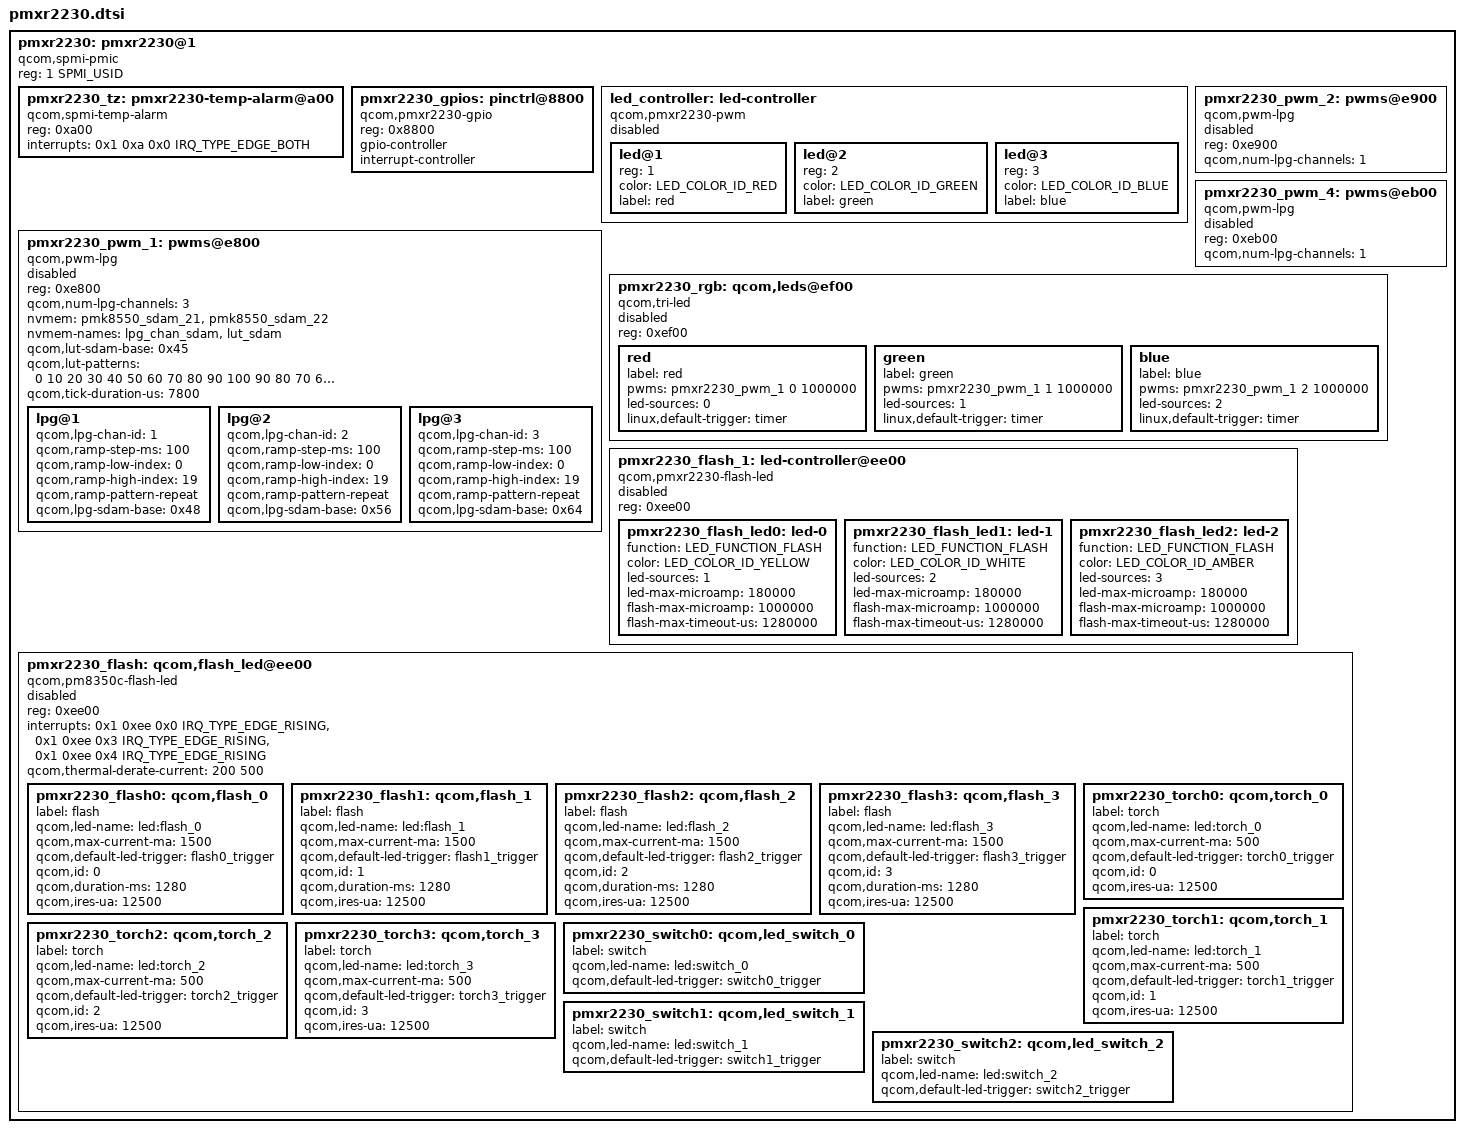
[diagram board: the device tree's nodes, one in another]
// SPDX-License-Identifier: BSD-3-Clause
/*
 * Copyright (c) Qualcomm Technologies, Inc. and/or its subsidiaries.
 */

#include <dt-bindings/interrupt-controller/irq.h>
#include <dt-bindings/spmi/spmi.h>
#include <dt-bindings/leds/common.h>

pmxr2230: pmxr2230@1 {
	compatible = "qcom,spmi-pmic";
	reg = <1 SPMI_USID>;
	#address-cells = <1>;
	#size-cells = <0>;

	pmxr2230_tz: pmxr2230-temp-alarm@a00 {
		compatible = "qcom,spmi-temp-alarm";
		reg = <0xa00>;
		interrupts = <0x1 0xa 0x0 IRQ_TYPE_EDGE_BOTH>;
		#thermal-sensor-cells = <0>;
	};

	pmxr2230_gpios: pinctrl@8800 {
		compatible = "qcom,pmxr2230-gpio";
		reg = <0x8800>;
		gpio-controller;
		#gpio-cells = <2>;
		interrupt-controller;
		#interrupt-cells = <2>;
	};

	led_controller: led-controller {
		compatible = "qcom,pmxr2230-pwm", "qcom,pm8350c-pwm";
		#address-cells = <1>;
		#size-cells = <0>;
		status = "disabled";

		led@1 {
			reg = <1>;
			color = <LED_COLOR_ID_RED>;
			label = "red";
		};

		led@2 {
			reg = <2>;
			color = <LED_COLOR_ID_GREEN>;
			label = "green";
		};

		led@3 {
			reg = <3>;
			color = <LED_COLOR_ID_BLUE>;
			label = "blue";
		};
	};

	pmxr2230_pwm_1: pwms@e800 {
		compatible = "qcom,pwm-lpg";
		reg = <0xe800>;
		reg-names = "lpg-base";
		#pwm-cells = <2>;
		qcom,num-lpg-channels = <3>;
		nvmem = <&pmk8550_sdam_21 &pmk8550_sdam_22>;
		nvmem-names = "lpg_chan_sdam", "lut_sdam";
		qcom,lut-sdam-base = <0x45>;
		qcom,lut-patterns = <0 10 20 30 40 50 60 70 80 90 100
				     90 80 70 60 50 40 30 20 10 0>;
		qcom,tick-duration-us = <7800>;
		status = "disabled";

		lpg@1 {
			qcom,lpg-chan-id = <1>;
			qcom,ramp-step-ms = <100>;
			qcom,ramp-low-index = <0>;
			qcom,ramp-high-index = <19>;
			qcom,ramp-pattern-repeat;
			qcom,lpg-sdam-base = <0x48>;
		};

		lpg@2 {
			qcom,lpg-chan-id = <2>;
			qcom,ramp-step-ms = <100>;
			qcom,ramp-low-index = <0>;
			qcom,ramp-high-index = <19>;
			qcom,ramp-pattern-repeat;
			qcom,lpg-sdam-base = <0x56>;
		};

		lpg@3 {
			qcom,lpg-chan-id = <3>;
			qcom,ramp-step-ms = <100>;
			qcom,ramp-low-index = <0>;
			qcom,ramp-high-index = <19>;
			qcom,ramp-pattern-repeat;
			qcom,lpg-sdam-base = <0x64>;
		};
	};

	pmxr2230_pwm_2: pwms@e900 {
		compatible = "qcom,pwm-lpg";
		reg = <0xe900>;
		reg-names = "lpg-base";
		#pwm-cells = <2>;
		qcom,num-lpg-channels = <1>;
		status = "disabled";
	};

	pmxr2230_pwm_4: pwms@eb00 {
		compatible = "qcom,pwm-lpg";
		reg = <0xeb00>;
		reg-names = "lpg-base";
		#pwm-cells = <2>;
		qcom,num-lpg-channels = <1>;
		status = "disabled";
	};

	pmxr2230_rgb: qcom,leds@ef00 {
		compatible = "qcom,tri-led";
		reg = <0xef00>;
		status = "disabled";

		red {
			label = "red";
			pwms = <&pmxr2230_pwm_1 0 1000000>;
			led-sources = <0>;
			linux,default-trigger = "timer";
		};

		green {
			label = "green";
			pwms = <&pmxr2230_pwm_1 1 1000000>;
			led-sources = <1>;
			linux,default-trigger = "timer";
		};

		blue {
			label = "blue";
			pwms = <&pmxr2230_pwm_1 2 1000000>;
			led-sources = <2>;
			linux,default-trigger = "timer";
		};
	};

	pmxr2230_flash_1: led-controller@ee00 {
		compatible = "qcom,pmxr2230-flash-led", "qcom,spmi-flash-led";
		reg = <0xee00>;
		status = "disabled";

		pmxr2230_flash_led0: led-0 {
			function = LED_FUNCTION_FLASH;
			color = <LED_COLOR_ID_YELLOW>;
			led-sources = <1>;
			led-max-microamp = <180000>;
			flash-max-microamp = <1000000>;
			flash-max-timeout-us = <1280000>;
		};

		pmxr2230_flash_led1: led-1 {
			function = LED_FUNCTION_FLASH;
			color = <LED_COLOR_ID_WHITE>;
			led-sources = <2>;
			led-max-microamp = <180000>;
			flash-max-microamp = <1000000>;
			flash-max-timeout-us = <1280000>;
		};

		pmxr2230_flash_led2: led-2 {
			function = LED_FUNCTION_FLASH;
			color = <LED_COLOR_ID_AMBER>;
			led-sources = <3>;
			led-max-microamp = <180000>;
			flash-max-microamp = <1000000>;
			flash-max-timeout-us = <1280000>;
		};
	};

	pmxr2230_flash: qcom,flash_led@ee00 {
		compatible = "qcom,pm8350c-flash-led";
		reg = <0xee00>;
		interrupts = <0x1 0xee 0x0 IRQ_TYPE_EDGE_RISING>,
			     <0x1 0xee 0x3 IRQ_TYPE_EDGE_RISING>,
			     <0x1 0xee 0x4 IRQ_TYPE_EDGE_RISING>;
		interrupt-names = "led-fault-irq",
				  "all-ramp-down-done-irq",
				  "all-ramp-up-done-irq";
		qcom,thermal-derate-current = <200 500>;
		status = "disabled";

		pmxr2230_flash0: qcom,flash_0 {
			label = "flash";
			qcom,led-name = "led:flash_0";
			qcom,max-current-ma = <1500>;
			qcom,default-led-trigger = "flash0_trigger";
			qcom,id = <0>;
			qcom,duration-ms = <1280>;
			qcom,ires-ua = <12500>;
		};

		pmxr2230_flash1: qcom,flash_1 {
			label = "flash";
			qcom,led-name = "led:flash_1";
			qcom,max-current-ma = <1500>;
			qcom,default-led-trigger = "flash1_trigger";
			qcom,id = <1>;
			qcom,duration-ms = <1280>;
			qcom,ires-ua = <12500>;
		};

		pmxr2230_flash2: qcom,flash_2 {
			label = "flash";
			qcom,led-name = "led:flash_2";
			qcom,max-current-ma = <1500>;
			qcom,default-led-trigger = "flash2_trigger";
			qcom,id = <2>;
			qcom,duration-ms = <1280>;
			qcom,ires-ua = <12500>;
		};

		pmxr2230_flash3: qcom,flash_3 {
			label = "flash";
			qcom,led-name = "led:flash_3";
			qcom,max-current-ma = <1500>;
			qcom,default-led-trigger = "flash3_trigger";
			qcom,id = <3>;
			qcom,duration-ms = <1280>;
			qcom,ires-ua = <12500>;
		};

		pmxr2230_torch0: qcom,torch_0 {
			label = "torch";
			qcom,led-name = "led:torch_0";
			qcom,max-current-ma = <500>;
			qcom,default-led-trigger = "torch0_trigger";
			qcom,id = <0>;
			qcom,ires-ua = <12500>;
		};

		pmxr2230_torch1: qcom,torch_1 {
			label = "torch";
			qcom,led-name = "led:torch_1";
			qcom,max-current-ma = <500>;
			qcom,default-led-trigger = "torch1_trigger";
			qcom,id = <1>;
			qcom,ires-ua = <12500>;
		};

		pmxr2230_torch2: qcom,torch_2 {
			label = "torch";
			qcom,led-name = "led:torch_2";
			qcom,max-current-ma = <500>;
			qcom,default-led-trigger = "torch2_trigger";
			qcom,id = <2>;
			qcom,ires-ua = <12500>;
		};

		pmxr2230_torch3: qcom,torch_3 {
			label = "torch";
			qcom,led-name = "led:torch_3";
			qcom,max-current-ma = <500>;
			qcom,default-led-trigger = "torch3_trigger";
			qcom,id = <3>;
			qcom,ires-ua = <12500>;
		};

		pmxr2230_switch0: qcom,led_switch_0 {
			label = "switch";
			qcom,led-name = "led:switch_0";
			qcom,default-led-trigger = "switch0_trigger";
		};

		pmxr2230_switch1: qcom,led_switch_1 {
			label = "switch";
			qcom,led-name = "led:switch_1";
			qcom,default-led-trigger = "switch1_trigger";
		};

		pmxr2230_switch2: qcom,led_switch_2 {
			label = "switch";
			qcom,led-name = "led:switch_2";
			qcom,default-led-trigger = "switch2_trigger";
		};
	};
};
